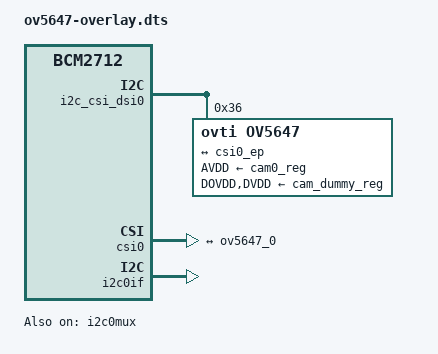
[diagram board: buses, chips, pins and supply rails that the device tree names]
/*
 * Pi Camera Module v1 (OV5647) Device Tree Overlay
 * Raspberry Pi 5 - MIPI CSI-2
 */

/dts-v1/;
/plugin/;

/ {
    compatible = "brcm,bcm2712";
    
    fragment@0 {
        target = <&i2c_csi_dsi0>;
        __overlay__ {
            #address-cells = <1>;
            #size-cells = <0>;
            status = "okay";
            
            ov5647: ov5647@36 {
                compatible = "ovti,ov5647";
                reg = <0x36>;
                status = "okay";
                
                clocks = <&cam0_clk>;
                clock-names = "xclk";
                
                AVDD-supply = <&cam0_reg>;
                DOVDD-supply = <&cam_dummy_reg>;
                DVDD-supply = <&cam_dummy_reg>;
                
                rotation = <0>;
                orientation = <2>;
                
                port {
                    ov5647_0: endpoint {
                        remote-endpoint = <&csi0_ep>;
                        clock-lanes = <0>;
                        data-lanes = <1 2>;
                        link-frequencies = /bits/ 64 <297000000>;
                    };
                };
            };
        };
    };
    
    fragment@1 {
        target = <&csi0>;
        __overlay__ {
            status = "okay";
            
            port {
                csi0_ep: endpoint {
                    remote-endpoint = <&ov5647_0>;
                    data-lanes = <1 2>;
                };
            };
        };
    };
    
    fragment@2 {
        target = <&i2c0if>;
        __overlay__ {
            status = "okay";
        };
    };
    
    fragment@3 {
        target = <&i2c0mux>;
        __overlay__ {
            status = "okay";
        };
    };
    
    __overrides__ {
        rotation = <&ov5647>,"rotation:0";
        orientation = <&ov5647>,"orientation:0";
        media-controller = <&csi0>,"brcm,media-controller?";
        cam0 = <&ov5647>, "status";
    };
};
